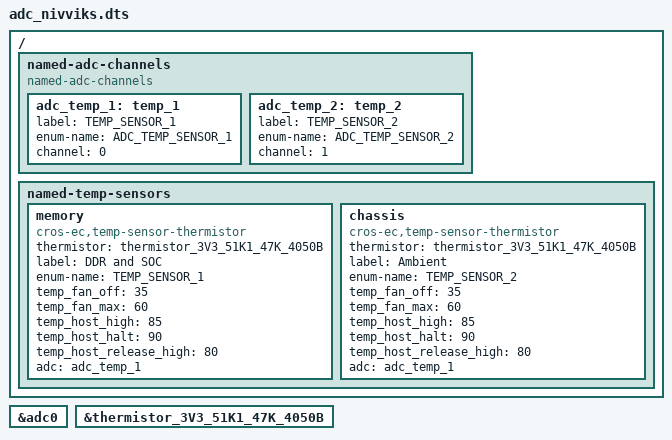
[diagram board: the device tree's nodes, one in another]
/* Copyright 2021 The Chromium OS Authors. All rights reserved.
 * Use of this source code is governed by a BSD-style license that can be
 * found in the LICENSE file.
 */

#include <cros/thermistor/thermistor.dtsi>

/ {
	named-adc-channels {
		compatible = "named-adc-channels";

		adc_temp_1: temp_1 {
			label = "TEMP_SENSOR_1";
			enum-name = "ADC_TEMP_SENSOR_1";
			channel = <0>;
		};
		adc_temp_2: temp_2 {
			label = "TEMP_SENSOR_2";
			enum-name = "ADC_TEMP_SENSOR_2";
			channel = <1>;
		};
	};

	named-temp-sensors {
		memory {
			compatible = "cros-ec,temp-sensor-thermistor";
			thermistor = <&thermistor_3V3_51K1_47K_4050B>;
			label = "DDR and SOC";
			enum-name = "TEMP_SENSOR_1";
			temp_fan_off = <35>;
			temp_fan_max = <60>;
			temp_host_high = <85>;
			temp_host_halt = <90>;
			temp_host_release_high = <80>;
			adc = <&adc_temp_1>;
		};
		chassis {
			compatible = "cros-ec,temp-sensor-thermistor";
			thermistor = <&thermistor_3V3_51K1_47K_4050B>;
			label = "Ambient";
			enum-name = "TEMP_SENSOR_2";
			temp_fan_off = <35>;
			temp_fan_max = <60>;
			temp_host_high = <85>;
			temp_host_halt = <90>;
			temp_host_release_high = <80>;
			adc = <&adc_temp_1>;
		};
	};
};

&adc0 {
	status = "okay";
};

&thermistor_3V3_51K1_47K_4050B {
	status = "okay";
};
